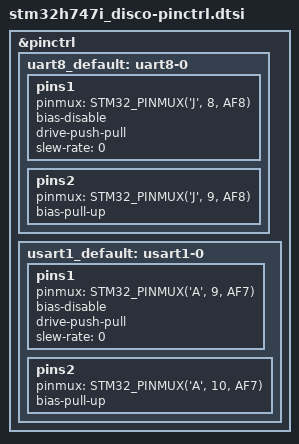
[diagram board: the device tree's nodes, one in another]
// SPDX-FileCopyrightText: 2026 Core Devices LLC
// SPDX-License-Identifier: (GPL-2.0-only OR BSD-2-Clause)

&pinctrl {
	// D1 (TX) and D0 (RX) of the Arduino connector
	uart8_default: uart8-0 {
		pins1 {
			pinmux = <STM32_PINMUX('J', 8, AF8)>; /* UART8_TX */
			bias-disable;
			drive-push-pull;
			slew-rate = <0>;
		};

		pins2 {
			pinmux = <STM32_PINMUX('J', 9, AF8)>; /* UART8_RX */
			bias-pull-up;
		};
	};

	// ST-LINK virtual COM port
	usart1_default: usart1-0 {
		pins1 {
			pinmux = <STM32_PINMUX('A', 9, AF7)>; /* USART1_TX */
			bias-disable;
			drive-push-pull;
			slew-rate = <0>;
		};

		pins2 {
			pinmux = <STM32_PINMUX('A', 10, AF7)>; /* USART1_RX */
			bias-pull-up;
		};
	};
};
